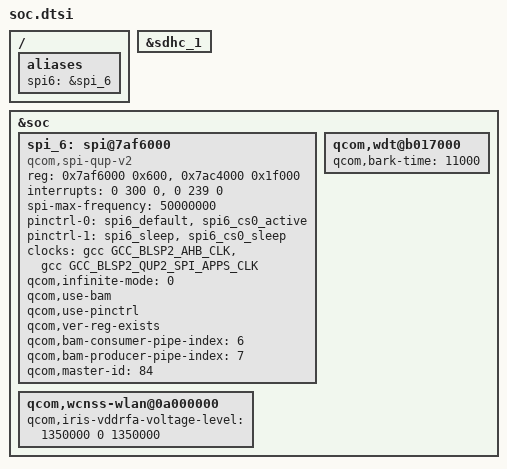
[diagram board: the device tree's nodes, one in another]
/ {
	aliases {
		/delete-property/ i2c4;
		spi6 = &spi_6;
	};
};

&sdhc_1 {
	/delete-property/ qcom,ddr-config;
};

&soc {
	/delete-node/ i2c@78b8000;

	spi_6: spi@7af6000 { /* BLSP2 QUP2 */
		compatible = "qcom,spi-qup-v2";
		#address-cells = <1>;
		#size-cells = <0>;
		reg-names = "spi_physical", "spi_bam_physical";
		reg = <0x7af6000 0x600>,
			<0x7ac4000 0x1f000>;
		interrupt-names = "spi_irq", "spi_bam_irq";
		interrupts = <0 300 0>, <0 239 0>;
		spi-max-frequency = <50000000>;
		pinctrl-names = "spi_default", "spi_sleep";
		pinctrl-0 = <&spi6_default &spi6_cs0_active>;
		pinctrl-1 = <&spi6_sleep &spi6_cs0_sleep>;
		clocks = <&gcc GCC_BLSP2_AHB_CLK>,
			<&gcc GCC_BLSP2_QUP2_SPI_APPS_CLK>;
		clock-names = "iface_clk", "core_clk";
		qcom,infinite-mode = <0>;
		qcom,use-bam;
		qcom,use-pinctrl;
		qcom,ver-reg-exists;
		qcom,bam-consumer-pipe-index = <6>;
		qcom,bam-producer-pipe-index = <7>;
		qcom,master-id = <84>;
	};

	qcom,wcnss-wlan@0a000000 {
		qcom,iris-vddrfa-voltage-level = <1350000 0 1350000>;
	};

	qcom,wdt@b017000 {
		qcom,bark-time = <11000>;
	};
};
